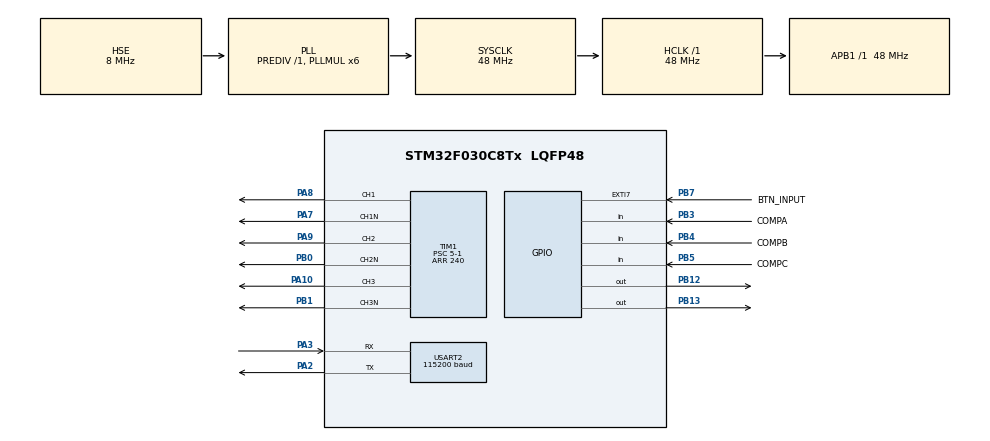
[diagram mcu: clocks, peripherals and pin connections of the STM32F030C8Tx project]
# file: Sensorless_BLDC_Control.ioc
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Mcu.Family=STM32F0
Mcu.Name=STM32F030C8Tx
Mcu.Package=LQFP48
NVIC.EXTI4_15_IRQn=true\:1\:0\:true\:false\:true\:true\:false\:true
NVIC.TIM14_IRQn=true\:0\:0\:false\:false\:true\:true\:false\:true
NVIC.TIM1_BRK_UP_TRG_COM_IRQn=true\:0\:0\:false\:false\:true\:true\:false\:true
NVIC.TIM6_IRQn=true\:0\:0\:false\:false\:true\:true\:false\:true
NVIC.USART2_IRQn=true\:2\:0\:true\:false\:true\:true\:false\:true
PA10.Signal=S_TIM1_CH3
PA13.Mode=Serial_Wire
PA13.Signal=SYS_SWDIO
PA14.Mode=Serial_Wire
PA14.Signal=SYS_SWCLK
PA2.Mode=Asynchronous
PA2.Signal=USART2_TX
PA3.Mode=Asynchronous
PA3.Signal=USART2_RX
PA7.Mode=PWM Generation1 CH1 CH1N
PA7.Signal=TIM1_CH1N
PA8.Signal=S_TIM1_CH1
PA9.Signal=S_TIM1_CH2
PB0.Mode=PWM Generation2 CH2 CH2N
PB0.Signal=TIM1_CH2N
PB1.Mode=PWM Generation3 CH3 CH3N
PB1.Signal=TIM1_CH3N
PB12.Signal=GPIO_Output
PB13.Signal=GPIO_Output
PB3.GPIO_Label=COMPA
PB3.Signal=GPIO_Input
PB4.GPIO_Label=COMPB
PB4.Signal=GPIO_Input
PB5.GPIO_Label=COMPC
PB5.Signal=GPIO_Input
PB7.GPIO_Label=BTN_INPUT
PB7.GPIO_ModeDefaultEXTI=GPIO_MODE_IT_FALLING
PB7.Signal=GPXTI7
PC14-OSC32_IN.Mode=LSE-External-Oscillator
PC14-OSC32_IN.Signal=RCC_OSC32_IN
PC15-OSC32_OUT.Mode=LSE-External-Oscillator
PC15-OSC32_OUT.Signal=RCC_OSC32_OUT
PF0-OSC_IN.Mode=HSE-External-Oscillator
PF0-OSC_IN.Signal=RCC_OSC_IN
PF1-OSC_OUT.Mode=HSE-External-Oscillator
PF1-OSC_OUT.Signal=RCC_OSC_OUT
ProjectManager.HeapSize=0x200
ProjectManager.StackSize=0x400
ProjectManager.TargetToolchain=STM32CubeIDE
RCC.AHBFreq_Value=48000000
RCC.APB1Freq_Value=48000000
RCC.APB1TimFreq_Value=48000000
RCC.EnbaleCSS=true
RCC.HCLKFreq_Value=48000000
RCC.PLLMUL=RCC_PLL_MUL6
RCC.PLLSourceVirtual=RCC_PLLSOURCE_HSE
RCC.SYSCLKFreq_VALUE=48000000
RCC.SYSCLKSource=RCC_SYSCLKSOURCE_PLLCLK
SH.S_TIM1_CH1.0=TIM1_CH1,PWM Generation1 CH1 CH1N
SH.S_TIM1_CH2.0=TIM1_CH2,PWM Generation2 CH2 CH2N
SH.S_TIM1_CH3.0=TIM1_CH3,PWM Generation3 CH3 CH3N
TIM1.AutoReloadPreload=TIM_AUTORELOAD_PRELOAD_ENABLE
TIM1.Channel-PWM\ Generation1\ CH1\ CH1N=TIM_CHANNEL_1
TIM1.Channel-PWM\ Generation2\ CH2\ CH2N=TIM_CHANNEL_2
TIM1.Channel-PWM\ Generation3\ CH3\ CH3N=TIM_CHANNEL_3
TIM1.CounterMode=TIM_COUNTERMODE_CENTERALIGNED1
TIM1.DeadTime=96
TIM1.OCMode_PWM-PWM\ Generation2\ CH2\ CH2N=TIM_OCMODE_PWM1
TIM1.Period=240
TIM1.Prescaler=5-1
TIM1.RepetitionCounter=0
TIM1.TIM_MasterOutputTrigger=TIM_TRGO_UPDATE
TIM14.Prescaler=48-1
TIM3.AutoReloadPreload=TIM_AUTORELOAD_PRELOAD_DISABLE
TIM3.Prescaler=48-1
TIM6.Prescaler=48-1
USART2.BaudRate=115200
USART2.VirtualMode-Asynchronous=VM_ASYNC
VP_TIM14_VS_ClockSourceINT.Mode=Enable_Timer
VP_TIM1_VS_ClockSourceINT.Mode=Internal
VP_TIM3_VS_ClockSourceINT.Mode=Internal
VP_TIM6_VS_ClockSourceINT.Mode=Enable_Timer
board=custom

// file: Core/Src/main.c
/* USER CODE BEGIN Header */
/**
  ******************************************************************************
  * @file           : main.c
  * @brief          : Main program body
  ******************************************************************************
  * @attention
  *
  * Copyright (c) 2026 STMicroelectronics.
  * All rights reserved.
  *
  * This software is licensed under terms that can be found in the LICENSE file
  * in the root directory of this software component.
  * If no LICENSE file comes with this software, it is provided AS-IS.
  *
  ******************************************************************************
  */
/* USER CODE END Header */
#include "main.h"

/* USER CODE BEGIN Includes */

#include "driver/TIM3_us_driver.h"
#include "driver/uart_driver.h"

#include "service/bldc_service.h"
#include "service/uart_service.h"

/* USER CODE END Includes */

TIM_HandleTypeDef htim1;
TIM_HandleTypeDef htim3;
TIM_HandleTypeDef htim6;
TIM_HandleTypeDef htim14;

UART_HandleTypeDef huart2;

void SystemClock_Config(void);
static void MX_GPIO_Init(void);
static void MX_TIM1_Init(void);
static void MX_TIM3_Init(void);
static void MX_TIM6_Init(void);
static void MX_USART2_UART_Init(void);
static void MX_TIM14_Init(void);

int main(void)
{

  /* MCU Configuration--------------------------------------------------------*/

  /* Reset of all peripherals, Initializes the Flash interface and the Systick. */
  HAL_Init();

  /* Configure the system clock */
  SystemClock_Config();

  /* Initialize all configured peripherals */
  MX_GPIO_Init();
  MX_TIM1_Init();
  MX_TIM3_Init();
  MX_TIM6_Init();
  MX_USART2_UART_Init();
  MX_TIM14_Init();
  /* USER CODE BEGIN 2 */

  BLDC_Service_Inite();  //타이머 인터럽트 내의 콜백함수 주소를 지정
  HAL_TIM_Base_Start(&htim3);
  HAL_TIM_Base_Start_IT(&htim6);
  HAL_TIM_Base_Start_IT(&htim14);

  UART_Service_Initie();	//에러플래그 비트인터럽트 활성화, 수신인터럽트 활성화

  /* USER CODE END 2 */

  /* Infinite loop */
  while (1)
  {

    /* USER CODE BEGIN 3 */
	UART_Service_CLI();
	BLDC_Service();

  }
  /* USER CODE END 3 */
}

void SystemClock_Config(void)
{
  RCC_OscInitTypeDef RCC_OscInitStruct = {0};
  RCC_ClkInitTypeDef RCC_ClkInitStruct = {0};

  /** Initializes the RCC Oscillators according to the specified parameters
  * in the RCC_OscInitTypeDef structure.
  */
  RCC_OscInitStruct.OscillatorType = RCC_OSCILLATORTYPE_HSE;
  RCC_OscInitStruct.HSEState = RCC_HSE_ON;
  RCC_OscInitStruct.PLL.PLLState = RCC_PLL_ON;
  RCC_OscInitStruct.PLL.PLLSource = RCC_PLLSOURCE_HSE;
  RCC_OscInitStruct.PLL.PLLMUL = RCC_PLL_MUL6;
  RCC_OscInitStruct.PLL.PREDIV = RCC_PREDIV_DIV1;
  if (HAL_RCC_OscConfig(&RCC_OscInitStruct) != HAL_OK)
  {
    Error_Handler();
  }

  /** Initializes the CPU, AHB and APB buses clocks
  */
  RCC_ClkInitStruct.ClockType = RCC_CLOCKTYPE_HCLK|RCC_CLOCKTYPE_SYSCLK
                              |RCC_CLOCKTYPE_PCLK1;
  RCC_ClkInitStruct.SYSCLKSource = RCC_SYSCLKSOURCE_PLLCLK;
  RCC_ClkInitStruct.AHBCLKDivider = RCC_SYSCLK_DIV1;
  RCC_ClkInitStruct.APB1CLKDivider = RCC_HCLK_DIV1;

  if (HAL_RCC_ClockConfig(&RCC_ClkInitStruct, FLASH_LATENCY_1) != HAL_OK)
  {
    Error_Handler();
  }

  /** Enables the Clock Security System
  */
  HAL_RCC_EnableCSS();
}

static void MX_TIM1_Init(void)
{

  TIM_ClockConfigTypeDef sClockSourceConfig = {0};
  TIM_MasterConfigTypeDef sMasterConfig = {0};
  TIM_OC_InitTypeDef sConfigOC = {0};
  TIM_BreakDeadTimeConfigTypeDef sBreakDeadTimeConfig = {0};

  htim1.Instance = TIM1;
  htim1.Init.Prescaler = 5-1;
  htim1.Init.CounterMode = TIM_COUNTERMODE_CENTERALIGNED1;
  htim1.Init.Period = 240;
  htim1.Init.ClockDivision = TIM_CLOCKDIVISION_DIV1;
  htim1.Init.RepetitionCounter = 0;
  htim1.Init.AutoReloadPreload = TIM_AUTORELOAD_PRELOAD_ENABLE;
  if (HAL_TIM_Base_Init(&htim1) != HAL_OK)
  {
    Error_Handler();
  }
  sClockSourceConfig.ClockSource = TIM_CLOCKSOURCE_INTERNAL;
  if (HAL_TIM_ConfigClockSource(&htim1, &sClockSourceConfig) != HAL_OK)
  {
    Error_Handler();
  }
  if (HAL_TIM_PWM_Init(&htim1) != HAL_OK)
  {
    Error_Handler();
  }
  sMasterConfig.MasterOutputTrigger = TIM_TRGO_UPDATE;
  sMasterConfig.MasterSlaveMode = TIM_MASTERSLAVEMODE_DISABLE;
  if (HAL_TIMEx_MasterConfigSynchronization(&htim1, &sMasterConfig) != HAL_OK)
  {
    Error_Handler();
  }
  sConfigOC.OCMode = TIM_OCMODE_PWM1;
  sConfigOC.Pulse = 0;
  sConfigOC.OCPolarity = TIM_OCPOLARITY_HIGH;
  sConfigOC.OCNPolarity = TIM_OCNPOLARITY_HIGH;
  sConfigOC.OCFastMode = TIM_OCFAST_DISABLE;
  sConfigOC.OCIdleState = TIM_OCIDLESTATE_RESET;
  sConfigOC.OCNIdleState = TIM_OCNIDLESTATE_RESET;
  if (HAL_TIM_PWM_ConfigChannel(&htim1, &sConfigOC, TIM_CHANNEL_1) != HAL_OK)
  {
    Error_Handler();
  }
  if (HAL_TIM_PWM_ConfigChannel(&htim1, &sConfigOC, TIM_CHANNEL_2) != HAL_OK)
  {
    Error_Handler();
  }
  if (HAL_TIM_PWM_ConfigChannel(&htim1, &sConfigOC, TIM_CHANNEL_3) != HAL_OK)
  {
    Error_Handler();
  }
  sBreakDeadTimeConfig.OffStateRunMode = TIM_OSSR_DISABLE;
  sBreakDeadTimeConfig.OffStateIDLEMode = TIM_OSSI_DISABLE;
  sBreakDeadTimeConfig.LockLevel = TIM_LOCKLEVEL_OFF;
  sBreakDeadTimeConfig.DeadTime = 96;
  sBreakDeadTimeConfig.BreakState = TIM_BREAK_DISABLE;
  sBreakDeadTimeConfig.BreakPolarity = TIM_BREAKPOLARITY_HIGH;
  sBreakDeadTimeConfig.AutomaticOutput = TIM_AUTOMATICOUTPUT_DISABLE;
  if (HAL_TIMEx_ConfigBreakDeadTime(&htim1, &sBreakDeadTimeConfig) != HAL_OK)
  {
    Error_Handler();
  }
  HAL_TIM_MspPostInit(&htim1);

}

static void MX_TIM3_Init(void)
{

  TIM_ClockConfigTypeDef sClockSourceConfig = {0};
  TIM_MasterConfigTypeDef sMasterConfig = {0};

  htim3.Instance = TIM3;
  htim3.Init.Prescaler = 48-1;
  htim3.Init.CounterMode = TIM_COUNTERMODE_UP;
  htim3.Init.Period = 65535;
  htim3.Init.ClockDivision = TIM_CLOCKDIVISION_DIV1;
  htim3.Init.AutoReloadPreload = TIM_AUTORELOAD_PRELOAD_DISABLE;
  if (HAL_TIM_Base_Init(&htim3) != HAL_OK)
  {
    Error_Handler();
  }
  sClockSourceConfig.ClockSource = TIM_CLOCKSOURCE_INTERNAL;
  if (HAL_TIM_ConfigClockSource(&htim3, &sClockSourceConfig) != HAL_OK)
  {
    Error_Handler();
  }
  sMasterConfig.MasterOutputTrigger = TIM_TRGO_RESET;
  sMasterConfig.MasterSlaveMode = TIM_MASTERSLAVEMODE_DISABLE;
  if (HAL_TIMEx_MasterConfigSynchronization(&htim3, &sMasterConfig) != HAL_OK)
  {
    Error_Handler();
  }

}

static void MX_TIM6_Init(void)
{

  htim6.Instance = TIM6;
  htim6.Init.Prescaler = 48-1;
  htim6.Init.CounterMode = TIM_COUNTERMODE_UP;
  htim6.Init.Period = 65535;
  htim6.Init.AutoReloadPreload = TIM_AUTORELOAD_PRELOAD_DISABLE;
  if (HAL_TIM_Base_Init(&htim6) != HAL_OK)
  {
    Error_Handler();
  }

}

static void MX_TIM14_Init(void)
{

  htim14.Instance = TIM14;
  htim14.Init.Prescaler = 48-1;
  htim14.Init.CounterMode = TIM_COUNTERMODE_UP;
  htim14.Init.Period = 65535;
  htim14.Init.ClockDivision = TIM_CLOCKDIVISION_DIV1;
  htim14.Init.AutoReloadPreload = TIM_AUTORELOAD_PRELOAD_DISABLE;
  if (HAL_TIM_Base_Init(&htim14) != HAL_OK)
  {
    Error_Handler();
  }

}

static void MX_USART2_UART_Init(void)
{

  huart2.Instance = USART2;
  huart2.Init.BaudRate = 115200;
  huart2.Init.WordLength = UART_WORDLENGTH_8B;
  huart2.Init.StopBits = UART_STOPBITS_1;
  huart2.Init.Parity = UART_PARITY_NONE;
  huart2.Init.Mode = UART_MODE_TX_RX;
  huart2.Init.HwFlowCtl = UART_HWCONTROL_NONE;
  huart2.Init.OverSampling = UART_OVERSAMPLING_16;
  huart2.Init.OneBitSampling = UART_ONE_BIT_SAMPLE_DISABLE;
  huart2.AdvancedInit.AdvFeatureInit = UART_ADVFEATURE_NO_INIT;
  if (HAL_UART_Init(&huart2) != HAL_OK)
  {
    Error_Handler();
  }

}

static void MX_GPIO_Init(void)
{
  GPIO_InitTypeDef GPIO_InitStruct = {0};

  /* GPIO Ports Clock Enable */
  __HAL_RCC_GPIOC_CLK_ENABLE();
  __HAL_RCC_GPIOF_CLK_ENABLE();
  __HAL_RCC_GPIOA_CLK_ENABLE();
  __HAL_RCC_GPIOB_CLK_ENABLE();

  /*Configure GPIO pin Output Level */
  HAL_GPIO_WritePin(GPIOB, GPIO_PIN_12|GPIO_PIN_13, GPIO_PIN_RESET);

  /*Configure GPIO pins : PB12 PB13 */
  GPIO_InitStruct.Pin = GPIO_PIN_12|GPIO_PIN_13;
  GPIO_InitStruct.Mode = GPIO_MODE_OUTPUT_PP;
  GPIO_InitStruct.Pull = GPIO_NOPULL;
  GPIO_InitStruct.Speed = GPIO_SPEED_FREQ_LOW;
  HAL_GPIO_Init(GPIOB, &GPIO_InitStruct);

  /*Configure GPIO pins : COMPA_Pin COMPB_Pin COMPC_Pin */
  GPIO_InitStruct.Pin = COMPA_Pin|COMPB_Pin|COMPC_Pin;
  GPIO_InitStruct.Mode = GPIO_MODE_INPUT;
  GPIO_InitStruct.Pull = GPIO_NOPULL;
  HAL_GPIO_Init(GPIOB, &GPIO_InitStruct);

  /*Configure GPIO pin : BTN_INPUT_Pin */
  GPIO_InitStruct.Pin = BTN_INPUT_Pin;
  GPIO_InitStruct.Mode = GPIO_MODE_IT_FALLING;
  GPIO_InitStruct.Pull = GPIO_NOPULL;
  HAL_GPIO_Init(BTN_INPUT_GPIO_Port, &GPIO_InitStruct);

  /* EXTI interrupt init*/
  HAL_NVIC_SetPriority(EXTI4_15_IRQn, 1, 0);
  HAL_NVIC_EnableIRQ(EXTI4_15_IRQn);

}

void Error_Handler(void)
{
  __disable_irq();
  while (1)
  {
  }
}
